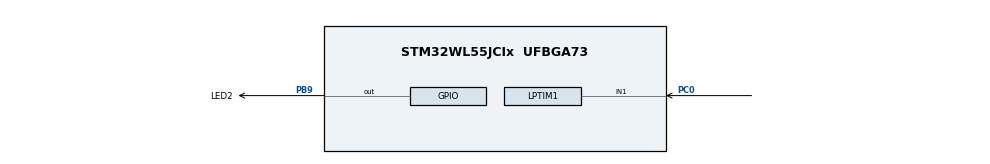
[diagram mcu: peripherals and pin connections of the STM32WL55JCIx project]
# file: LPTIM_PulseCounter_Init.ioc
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LPTIM1.TriggerSource=LPTIM_TRIGSOURCE_SOFTWARE
LPTIM1.ULPClockPolarity=LPTIM_CLOCKPOLARITY_RISING
LPTIM1.ULPClockSampleTime=LPTIM_CLOCKSAMPLETIME_DIRECTTRANSITION
LPTIM1.UpdateMode=LPTIM_UPDATE_IMMEDIATE
Mcu.Family=STM32WL
Mcu.Name=STM32WL55JCIx
Mcu.Package=UFBGA73
NVIC.LPTIM1_IRQn=true\:0\:0\:false\:false\:true\:true\:true
NVIC.PriorityGroup=NVIC_PRIORITYGROUP_4
PB9.GPIO_Label=LED2
PB9.Signal=GPIO_Output
PC0.GPIO_PuPd=GPIO_PULLDOWN
PC0.GPIO_Speed=GPIO_SPEED_FREQ_HIGH
PC0.Mode=Counts_external_clock_with_synchro_01_occur1
PC0.Signal=LPTIM1_IN1
ProjectManager.HeapSize=0x200
ProjectManager.StackSize=0x400
ProjectManager.TargetToolchain=EWARM V8
RCC.AHBFreq_Value=48000000
RCC.APB1Freq_Value=48000000
RCC.APB1TimFreq_Value=48000000
RCC.APB2Freq_Value=48000000
RCC.APB2TimFreq_Value=48000000
RCC.APB3Freq_Value=48000000
RCC.CortexFreq_Value=48000000
RCC.HCLKFreq_Value=48000000
RCC.HSE_VALUE=8000000
RCC.HSI_VALUE=16000000
RCC.LPTIM1CLockSelection=RCC_LPTIM1CLKSOURCE_LSI
RCC.LSE_VALUE=32768
RCC.MSIClockRange=RCC_MSIRANGE_11
RCC.SYSCLKFreq_VALUE=48000000
RCC.VCOOutputFreq_Value=384000000
board=custom

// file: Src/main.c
/* USER CODE BEGIN Header */
/**
  ******************************************************************************
  * @file    Examples_LL/LPTIM/LPTIM_PulseCounter_Init/Src/main.c
  * @author  MCD Application Team
  * @brief   This example describes how to use the LPTIM in counter mode
  *          using the STM32WLxx LPTIM LL API.
  *          Peripheral initialization done using LL initialization function.
  ******************************************************************************
  * @attention
  *
  * <h2><center>&copy; Copyright (c) 2020 STMicroelectronics.
  * All rights reserved.</center></h2>
  *
  * This software component is licensed by ST under BSD 3-Clause license,
  * the "License"; You may not use this file except in compliance with the
  * License. You may obtain a copy of the License at:
  *                        opensource.org/licenses/BSD-3-Clause
  *
  ******************************************************************************
  */
/* USER CODE END Header */
#include "main.h"

void SystemClock_Config(void);
static void MX_GPIO_Init(void);
static void MX_LPTIM1_Init(void);
/* USER CODE BEGIN PFP */
void EnterStop1Mode(void);
/* USER CODE END PFP */

int main(void)
{

  /* MCU Configuration--------------------------------------------------------*/

  /* Reset of all peripherals, Initializes the Flash interface and the Systick. */

  NVIC_SetPriorityGrouping(NVIC_PRIORITYGROUP_4);

  /* System interrupt init*/

  /* Configure the system clock */
  SystemClock_Config();

  /* Initialize all configured peripherals */
  MX_GPIO_Init();
  MX_LPTIM1_Init();
  /* USER CODE BEGIN 2 */

  /* Enter STOP 1 mode */
  EnterStop1Mode();

  /* USER CODE END 2 */

  /* Infinite loop */
  while (1)
  {

  }
}

void SystemClock_Config(void)
{
  LL_FLASH_SetLatency(LL_FLASH_LATENCY_2);
  while(LL_FLASH_GetLatency() != LL_FLASH_LATENCY_2)
  {
  }

  LL_PWR_SetRegulVoltageScaling(LL_PWR_REGU_VOLTAGE_SCALE1);
  LL_RCC_LSI_Enable();

   /* Wait till LSI is ready */
  while(LL_RCC_LSI_IsReady() != 1)
  {
  }

  LL_RCC_MSI_Enable();

   /* Wait till MSI is ready */
  while(LL_RCC_MSI_IsReady() != 1)
  {
  }

  LL_RCC_MSI_EnableRangeSelection();
  LL_RCC_MSI_SetRange(LL_RCC_MSIRANGE_11);
  LL_RCC_MSI_SetCalibTrimming(0);
  LL_RCC_SetSysClkSource(LL_RCC_SYS_CLKSOURCE_MSI);

   /* Wait till System clock is ready */
  while(LL_RCC_GetSysClkSource() != LL_RCC_SYS_CLKSOURCE_STATUS_MSI)
  {
  }

  LL_RCC_SetAHBPrescaler(LL_RCC_SYSCLK_DIV_1);
  LL_RCC_SetAHB3Prescaler(LL_RCC_SYSCLK_DIV_1);
  LL_RCC_SetAPB1Prescaler(LL_RCC_APB1_DIV_1);
  LL_RCC_SetAPB2Prescaler(LL_RCC_APB2_DIV_1);

  LL_Init1msTick(48000000);

  /* Update CMSIS variable (which can be updated also through SystemCoreClockUpdate function) */
  LL_SetSystemCoreClock(48000000);
}

static void MX_LPTIM1_Init(void)
{

  LL_GPIO_InitTypeDef GPIO_InitStruct = {0};

  LL_RCC_SetLPTIMClockSource(LL_RCC_LPTIM1_CLKSOURCE_LSI);

  /* Peripheral clock enable */
  LL_APB1_GRP1_EnableClock(LL_APB1_GRP1_PERIPH_LPTIM1);

  LL_AHB2_GRP1_EnableClock(LL_AHB2_GRP1_PERIPH_GPIOC);
  /**LPTIM1 GPIO Configuration
  PC0   ------> LPTIM1_IN1
  */
  GPIO_InitStruct.Pin = LL_GPIO_PIN_0;
  GPIO_InitStruct.Mode = LL_GPIO_MODE_ALTERNATE;
  GPIO_InitStruct.Speed = LL_GPIO_SPEED_FREQ_HIGH;
  GPIO_InitStruct.OutputType = LL_GPIO_OUTPUT_PUSHPULL;
  GPIO_InitStruct.Pull = LL_GPIO_PULL_DOWN;
  GPIO_InitStruct.Alternate = LL_GPIO_AF_1;
  LL_GPIO_Init(GPIOC, &GPIO_InitStruct);

  /* LPTIM1 interrupt Init */
  NVIC_SetPriority(LPTIM1_IRQn, NVIC_EncodePriority(NVIC_GetPriorityGrouping(),0, 0));
  NVIC_EnableIRQ(LPTIM1_IRQn);

  /* USER CODE BEGIN LPTIM1_Init 1 */

  /* LPTIM1 interrupts set-up */
  LL_EXTI_EnableIT_0_31(LL_EXTI_LINE_29);

  /* Enable the Autoreload match Interrupt */
  LL_LPTIM_EnableIT_ARRM(LPTIM1);

  /* USER CODE END LPTIM1_Init 1 */
  LL_LPTIM_SetClockSource(LPTIM1, LL_LPTIM_CLK_SOURCE_INTERNAL);
  LL_LPTIM_SetPrescaler(LPTIM1, LL_LPTIM_PRESCALER_DIV1);
  LL_LPTIM_SetPolarity(LPTIM1, LL_LPTIM_OUTPUT_POLARITY_REGULAR);
  LL_LPTIM_SetUpdateMode(LPTIM1, LL_LPTIM_UPDATE_MODE_IMMEDIATE);
  LL_LPTIM_SetCounterMode(LPTIM1, LL_LPTIM_COUNTER_MODE_EXTERNAL);
  LL_LPTIM_ConfigClock(LPTIM1, LL_LPTIM_CLK_FILTER_NONE, LL_LPTIM_CLK_POLARITY_RISING);
  LL_LPTIM_TrigSw(LPTIM1);
  LL_LPTIM_SetInput1Src(LPTIM1, LL_LPTIM_INPUT1_SRC_GPIO);
  LL_LPTIM_SetInput2Src(LPTIM1, LL_LPTIM_INPUT2_SRC_GPIO);
  /* USER CODE BEGIN LPTIM1_Init 2 */

  /* Enable the LPTIM1 counter */
  LL_LPTIM_Enable(LPTIM1);

  /* Set the Autoreload value */
  LL_LPTIM_SetAutoReload(LPTIM1, 1000);

  /* Start the LPTIM counter in continuous mode */
  LL_LPTIM_StartCounter(LPTIM1, LL_LPTIM_OPERATING_MODE_CONTINUOUS);

  /* USER CODE END LPTIM1_Init 2 */

}

static void MX_GPIO_Init(void)
{
  LL_GPIO_InitTypeDef GPIO_InitStruct = {0};

  /* GPIO Ports Clock Enable */
  LL_AHB2_GRP1_EnableClock(LL_AHB2_GRP1_PERIPH_GPIOB);
  LL_AHB2_GRP1_EnableClock(LL_AHB2_GRP1_PERIPH_GPIOC);

  /**/
  LL_GPIO_ResetOutputPin(LED2_GPIO_Port, LED2_Pin);

  /**/
  GPIO_InitStruct.Pin = LED2_Pin;
  GPIO_InitStruct.Mode = LL_GPIO_MODE_OUTPUT;
  GPIO_InitStruct.Speed = LL_GPIO_SPEED_FREQ_LOW;
  GPIO_InitStruct.OutputType = LL_GPIO_OUTPUT_PUSHPULL;
  GPIO_InitStruct.Pull = LL_GPIO_PULL_NO;
  LL_GPIO_Init(LED2_GPIO_Port, &GPIO_InitStruct);

}

/* USER CODE BEGIN 4 */

/**
  * @brief  Function to configure and enter in STOP 1 Mode.
  * @param  None
  * @retval None
  */
void EnterStop1Mode(void)
{
  /* Set low-power mode "Stop" */
  LL_PWR_SetPowerMode(LL_PWR_MODE_STOP1);

#if defined(DUAL_CORE)
  /* Set low-power mode "Stop" of CPU2 */
  /* Note: On STM32WL, both CPU1 and CPU2 must be in stop mode to set the entire system in stop mode */
  LL_C2_PWR_SetPowerMode(LL_PWR_MODE_STOP1);
#endif

  /* Set SLEEPDEEP bit of Cortex System Control Register */
  LL_LPM_EnableDeepSleep();

  /* Request Wait For Interrupt */
  __WFI();
}

/******************************************************************************/
/*   USER IRQ HANDLER TREATMENT                                               */
/******************************************************************************/
/**
  * @brief  LPTimer Autoreload match interrupt processing
  * @param  None
  * @retval None
  */
void LPTimerAutoreloadMatch_Callback(void)
{
  LL_GPIO_TogglePin(LED2_GPIO_Port, LED2_Pin);
}

/* USER CODE END 4 */

void Error_Handler(void)
{
}

/************************ (C) COPYRIGHT STMicroelectronics *****END OF FILE****/
